# STM32N645 register map
File version: 1.0
CPU: CM55 r0p1, little endian, no MPU, FPU, vendor SysTick, 8 interrupt priority bits
Registers are 32-bit, read-write, reset 0x0 unless marked. A register's access mark holds for its fields unless they carry their own. Offsets are from the block's base; [hi:lo] are bit positions; {n}, {i} and the like mark numbered series; 'fields as' and 'values as' point back to an identical list.

## OTG1 — USB on-the-go high-speed
Base 0x48040000
Same registers: OTG2 0x48080000, OTG1_S 0x58040000, OTG2_S 0x58080000
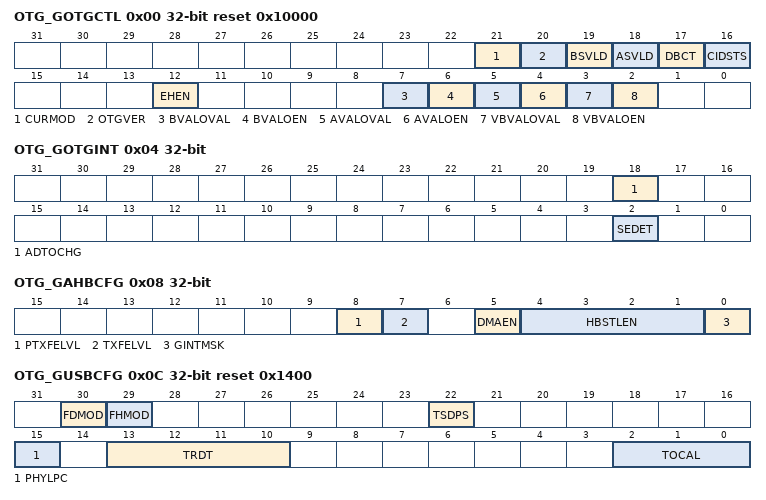
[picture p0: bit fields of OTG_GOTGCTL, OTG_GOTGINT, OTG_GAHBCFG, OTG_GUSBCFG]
0x00 OTG_GOTGCTL access per field reset 0x10000 — OTG control and status register
  [21] CURMOD ro — Current mode of operation
    0=Device mode; 1=Host mode
  [20] OTGVER rw — OTG version
    0=OTG Version 1.3. OTG1.3 is obsolete for new product development.; 1=OTG Version 2.0. In this version the core supports only data line pulsing for SRP.
  [19] BSVLD ro — B-session valid
    0=B-session is not valid; 1=B-session is valid
  [18] ASVLD ro — A-session valid
    0=A-session is not valid; 1=A-session is valid
  [17] DBCT ro — Long/short debounce time
    0=Long debounce time, used for physical connections (100 ms + 2.5 s); 1=Short debounce time, used for soft connections (2.5 s)
  [16] CIDSTS ro — Connector ID status
    0=The OTG controller is in A-device mode; 1=The OTG controller is in B-device mode
  [12] EHEN rw — Embedded host enable
    0=OTG A device state machine is selected; 1=Embedded host state machine is selected
  [7] BVALOVAL rw — B-peripheral session valid override value.
    0=Bvalid value is '0' when BVALOEN = 1; 1=Bvalid value is '1' when BVALOEN = 1
  [6] BVALOEN rw — B-peripheral session valid override enable.
    0=Override is disabled and Bvalid signal from the respective PHY selected is used internally by the core
  [5] AVALOVAL rw — A-peripheral session valid override value.
    0=Avalid value is '0' when AVALOEN = 1; 1=Avalid value is '1' when AVALOEN = 1
  [4] AVALOEN rw — A-peripheral session valid override enable.
    0=Override is disabled and Avalid signal from the respective PHY selected is used internally by the core; 1=Internally Avalid received from the PHY is overridden with AVALOVAL bit value
  [3] VBVALOVAL rw — V less than sub>BUS less than /sub> valid override value.
    0=vbusvalid value is '0' when VBVALOEN = 1; 1=vbusvalid value is '1' when VBVALOEN = 1
  [2] VBVALOEN rw — V less than sub>BUS less than /sub> valid override enable.
    0=Override is disabled and vbusvalid signal from the respective PHY selected is used internally by the core; 1=Internally vbusvalid received from the PHY is overridden with VBVALOVAL bit value
0x04 OTG_GOTGINT — OTG interrupt register
  [18] ADTOCHG — A-device timeout change
  [2] SEDET — Session end detected
0x08 OTG_GAHBCFG — OTG AHB configuration register
  [8] PTXFELVL — Periodic Tx FIFO empty level
    0=PTXFE (in OTG_GINTSTS) interrupt indicates that the Periodic Tx FIFO is half empty; 1=PTXFE (in OTG_GINTSTS) interrupt indicates that the Periodic Tx FIFO is completely empty
  [7] TXFELVL — Tx FIFO empty level
    0=B_0x0_DEVICE_MODE (The TXFE (in OTG_DIEPINTx) interrupt indicates that the IN endpoint Tx FIFO is half empty); 1=B_0x1_DEVICE_MODE (The TXFE (in OTG_DIEPINTx) interrupt indicates that the IN endpoint Tx FIFO is completely empty)
  [5] DMAEN — DMA enabled
    0=The core operates in slave mode; 1=The core operates in DMA mode
  [4:1] HBSTLEN — Burst length/type
  [0] GINTMSK — Global interrupt mask
    0=Mask the interrupt assertion to the application; 1=Unmask the interrupt assertion to the application
0x0C OTG_GUSBCFG reset 0x1400 — OTG USB configuration register
  [30] FDMOD — Force device mode
    0=Normal mode; 1=Force device mode
  [29] FHMOD — Force host mode
    0=Normal mode; 1=Force host mode
  [22] TSDPS — TermSel DLine pulsing selection
    0=Data line pulsing using utmi_txvalid (default); 1=Data line pulsing using utmi_termsel
  [15] PHYLPC — PHY Low-power clock select
    0=480 MHz internal PLL clock; 1=48 MHz external clock
  [13:10] TRDT — USB turnaround time
  [2:0] TOCAL — FS timeout calibration
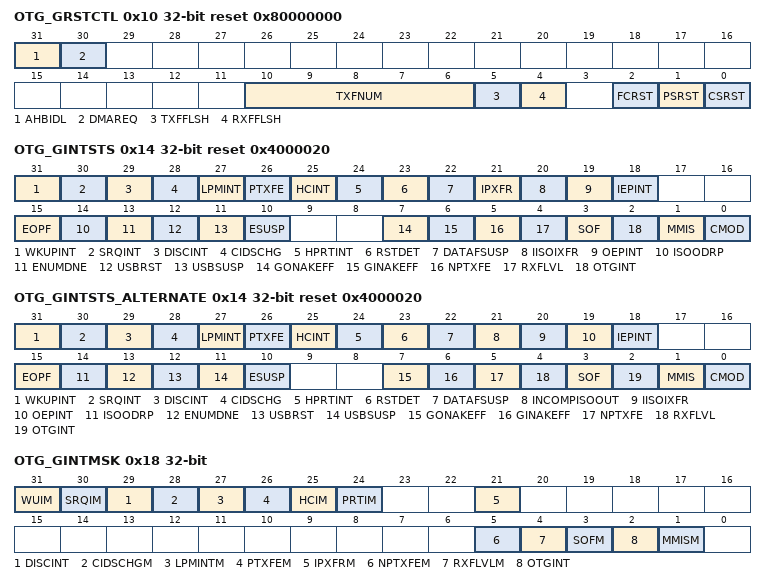
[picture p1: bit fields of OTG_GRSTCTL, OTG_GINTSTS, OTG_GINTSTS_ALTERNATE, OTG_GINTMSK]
0x10 OTG_GRSTCTL access per field reset 0x80000000 — OTG reset register
  [31] AHBIDL ro — AHB master idle
  [30] DMAREQ ro — DMA request signal enabled
  [10:6] TXFNUM rw — Tx FIFO number
    0=B_0x0_HOST_MODE (Non-periodic Tx FIFO flush); 1=B_0x1_HOST_MODE (Periodic Tx FIFO flush); 16=B_0x10_HOST_MODE (Flush all the transmit FIFOs); 2=B_0x2_DEVICE_MODE (Tx FIFO 2 flush); 15=B_0xF_DEVICE_MODE (Tx FIFO 15 flush)
  [5] TXFFLSH rw — Tx FIFO flush
  [4] RXFFLSH rw — Rx FIFO flush
  [2] FCRST rw — Host frame counter reset
  [1] PSRST rw — Partial soft reset
  [0] CSRST rw — Core soft reset
0x14 OTG_GINTSTS access per field reset 0x4000020 — OTG core interrupt register [alternate]
  [31] WKUPINT rw — Resume/remote wake-up detected interrupt
  [30] SRQINT rw — Session request/new session detected interrupt
  [29] DISCINT rw — Disconnect detected interrupt
  [28] CIDSCHG rw — Connector ID status change
  [27] LPMINT rw — LPM interrupt
  [26] PTXFE ro — Periodic Tx FIFO empty
  [25] HCINT ro — Host channels interrupt
  [24] HPRTINT ro — Host port interrupt
  [23] RSTDET rw — Reset detected interrupt
  [22] DATAFSUSP rw — Data fetch suspended
  [21] IPXFR rw — Incomplete periodic transfer
  [20] IISOIXFR rw — Incomplete isochronous IN transfer
  [19] OEPINT ro — OUT endpoint interrupt
  [18] IEPINT ro — IN endpoint interrupt
  [15] EOPF rw — End of periodic frame interrupt
  [14] ISOODRP rw — Isochronous OUT packet dropped interrupt
  [13] ENUMDNE rw — Enumeration done
  [12] USBRST rw — USB reset
  [11] USBSUSP rw — USB suspend
  [10] ESUSP rw — Early suspend
  [7] GONAKEFF ro — Global OUT NAK effective
  [6] GINAKEFF ro — Global IN non-periodic NAK effective
  [5] NPTXFE ro — Non-periodic Tx FIFO empty
  [4] RXFLVL ro — Rx FIFO non-empty
  [3] SOF rw — Start of frame
  [2] OTGINT ro — OTG interrupt
  [1] MMIS rw — Mode mismatch interrupt
  [0] CMOD ro — Current mode of operation
    0=Device mode; 1=Host mode
0x14 OTG_GINTSTS_ALTERNATE access per field reset 0x4000020 (alternate view of OTG_GINTSTS) — OTG core interrupt register [alternate]
  [31] WKUPINT rw — Resume/remote wake-up detected interrupt
  [30] SRQINT rw — Session request/new session detected interrupt
  [29] DISCINT rw — Disconnect detected interrupt
  [28] CIDSCHG rw — Connector ID status change
  [27] LPMINT rw — LPM interrupt
  [26] PTXFE ro — Periodic Tx FIFO empty
  [25] HCINT ro — Host channels interrupt
  [24] HPRTINT ro — Host port interrupt
  [23] RSTDET rw — Reset detected interrupt
  [22] DATAFSUSP rw — Data fetch suspended
  [21] INCOMPISOOUT rw — Incomplete isochronous OUT transfer
  [20] IISOIXFR rw — Incomplete isochronous IN transfer
  [19] OEPINT ro — OUT endpoint interrupt
  [18] IEPINT ro — IN endpoint interrupt
  [15] EOPF rw — End of periodic frame interrupt
  [14] ISOODRP rw — Isochronous OUT packet dropped interrupt
  [13] ENUMDNE rw — Enumeration done
  [12] USBRST rw — USB reset
  [11] USBSUSP rw — USB suspend
  [10] ESUSP rw — Early suspend
  [7] GONAKEFF ro — Global OUT NAK effective
  [6] GINAKEFF ro — Global IN non-periodic NAK effective
  [5] NPTXFE ro — Non-periodic Tx FIFO empty
  [4] RXFLVL ro — Rx FIFO non-empty
  [3] SOF rw — Start of frame
  [2] OTGINT ro — OTG interrupt
  [1] MMIS rw — Mode mismatch interrupt
  [0] CMOD ro — Current mode of operation
    0=Device mode; 1=Host mode
0x18 OTG_GINTMSK access per field — OTG interrupt mask register [alternate]
  [all] fields
    0=Masked interrupt; 1=Unmasked interrupt
  [31] WUIM rw — Resume/remote wake-up detected interrupt mask
  [30] SRQIM rw — Session request/new session detected interrupt mask
  [29] DISCINT rw — Disconnect detected interrupt mask
  [28] CIDSCHGM rw — Connector ID status change mask
  [27] LPMINTM rw — LPM interrupt mask
  [26] PTXFEM rw — Periodic Tx FIFO empty mask
  [25] HCIM rw — Host channels interrupt mask
  [24] PRTIM ro — Host port interrupt mask
  [21] IPXFRM rw — Incomplete periodic transfer mask
  [5] NPTXFEM rw — Non-periodic Tx FIFO empty mask
  [4] RXFLVLM rw — Receive FIFO non-empty mask
  [3] SOFM rw — Start of frame mask
  [2] OTGINT rw — OTG interrupt mask
  [1] MMISM rw — Mode mismatch interrupt mask
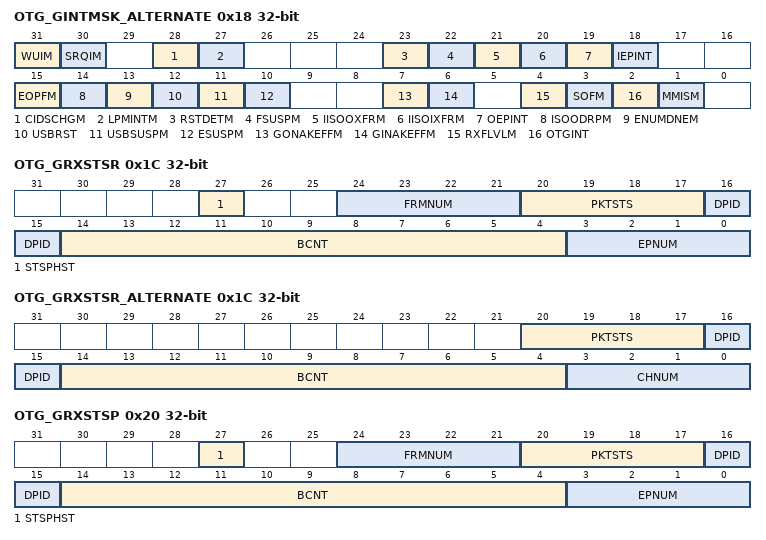
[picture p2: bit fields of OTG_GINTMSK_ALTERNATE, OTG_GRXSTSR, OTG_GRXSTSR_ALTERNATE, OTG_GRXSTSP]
0x18 OTG_GINTMSK_ALTERNATE (alternate view of OTG_GINTMSK) — OTG interrupt mask register [alternate]
  [all] fields
    0=Masked interrupt; 1=Unmasked interrupt
  [31] WUIM — Resume/remote wake-up detected interrupt mask
  [30] SRQIM — Session request/new session detected interrupt mask
  [28] CIDSCHGM — Connector ID status change mask
  [27] LPMINTM — LPM interrupt mask
  [23] RSTDETM — Reset detected interrupt mask
  [22] FSUSPM — Data fetch suspended mask
  [21] IISOOXFRM — Incomplete isochronous OUT transfer mask
  [20] IISOIXFRM — Incomplete isochronous IN transfer mask
  [19] OEPINT — OUT endpoints interrupt mask
  [18] IEPINT — IN endpoints interrupt mask
  [15] EOPFM — End of periodic frame interrupt mask
  [14] ISOODRPM — Isochronous OUT packet dropped interrupt mask
  [13] ENUMDNEM — Enumeration done mask
  [12] USBRST — USB reset mask
  [11] USBSUSPM — USB suspend mask
  [10] ESUSPM — Early suspend mask
  [7] GONAKEFFM — Global OUT NAK effective mask
  [6] GINAKEFFM — Global non-periodic IN NAK effective mask
  [4] RXFLVLM — Receive FIFO non-empty mask
  [3] SOFM — Start of frame mask
  [2] OTGINT — OTG interrupt mask
  [1] MMISM — Mode mismatch interrupt mask
0x1C OTG_GRXSTSR ro — OTG receive status debug read register [alternate]
  [27] STSPHST — Status phase start
  [24:21] FRMNUM — Frame number
  [20:17] PKTSTS — Packet status
    1=Global OUT NAK (triggers an interrupt); 2=OUT data packet received; 3=OUT transfer completed (triggers an interrupt); 4=SETUP transaction completed (triggers an interrupt); 6=SETUP data packet received
  [16:15] DPID — Data PID
    0=DATA0; 2=DATA1; 1=DATA2; 3=MDATA
  [14:4] BCNT — Byte count
  [3:0] EPNUM — Endpoint number
0x1C OTG_GRXSTSR_ALTERNATE ro (alternate view of OTG_GRXSTSR) — OTG receive status debug read register [alternate]
  [20:17] PKTSTS — Packet status
    2=IN data packet received; 3=IN transfer completed (triggers an interrupt); 5=Data toggle error (triggers an interrupt); 7=Channel halted (triggers an interrupt)
  [16:15] DPID — Data PID
    0=DATA0; 2=DATA1; 1=DATA2; 3=MDATA
  [14:4] BCNT — Byte count
  [3:0] CHNUM — Channel number
0x20 OTG_GRXSTSP ro — OTG status read and pop registers
  fields as OTG_GRXSTSR
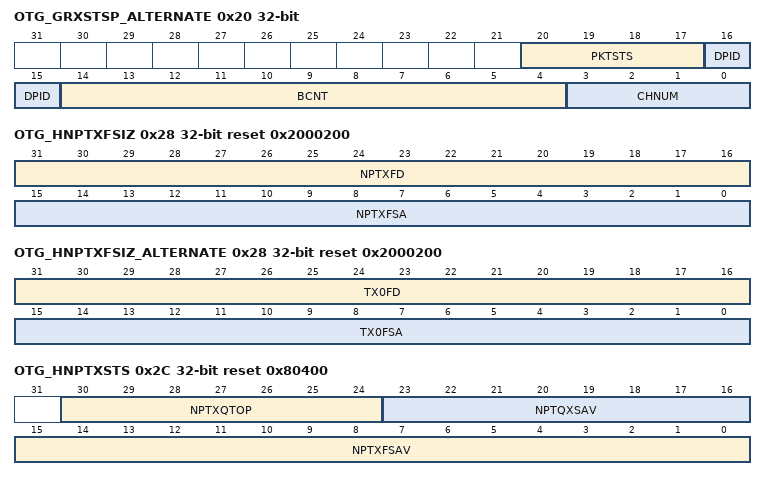
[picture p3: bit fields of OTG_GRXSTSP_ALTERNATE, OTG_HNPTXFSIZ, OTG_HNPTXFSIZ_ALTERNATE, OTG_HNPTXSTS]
0x20 OTG_GRXSTSP_ALTERNATE ro (alternate view of OTG_GRXSTSP) — OTG status read and pop registers
  fields as OTG_GRXSTSR_ALTERNATE
0x24 OTG_GRXFSIZ reset 0x400 — OTG receive FIFO size register
  [15:0] RXFD — Rx FIFO depth
0x28 OTG_HNPTXFSIZ reset 0x2000200 — OTG host non-periodic transmit FIFO size register [alternate]
  [31:16] NPTXFD — Non-periodic Tx FIFO depth
  [15:0] NPTXFSA — Non-periodic transmit RAM start address
0x28 OTG_HNPTXFSIZ_ALTERNATE reset 0x2000200 (alternate view of OTG_HNPTXFSIZ) — OTG host non-periodic transmit FIFO size register [alternate]
  [31:16] TX0FD — Endpoint 0 Tx FIFO depth
  [15:0] TX0FSA — Endpoint 0 transmit RAM start address
0x2C OTG_HNPTXSTS ro reset 0x80400 — OTG non-periodic transmit FIFO/queue status register
  [30:24] NPTXQTOP — Top of the non-periodic transmit request queue
  [23:16] NPTQXSAV — Non-periodic transmit request queue space available
    0=Non-periodic transmit request queue is full; 1=1 location available
  [15:0] NPTXFSAV — Non-periodic Tx FIFO space available
    0=Non-periodic Tx FIFO is full; 1=1 word available
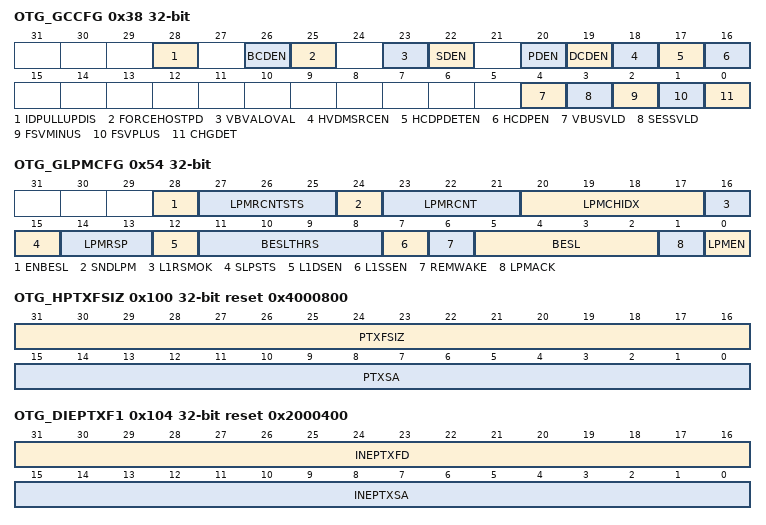
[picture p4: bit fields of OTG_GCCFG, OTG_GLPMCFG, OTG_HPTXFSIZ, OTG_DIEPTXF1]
0x38 OTG_GCCFG access per field (reset mask 0xFFFF0000) — OTG general core configuration register
  [28] IDPULLUPDIS rw — Disable ID pin pull-up
    0=Enables ID pin pull-up; 1=Disable ID pin pull-up
  [26] BCDEN rw — Force Battery charging (BC) mode
    0=Normal USB mode; 1=Battery Charging mode
  [25] FORCEHOSTPD rw — Force host mode pull-downs
    0=Do not force host mode pull-downs; 1=Force host mode pull-downs
  [23] VBVALOVAL rw — Software override value of the VBUS B-session detection
    0=B-session inactive; 1=B-session active
  [22] SDEN rw — Secondary detection enable
    0=Secondary detection disabled; 1=Secondary detection enabled
  [20] PDEN rw — Primary detection enable
    0=Primary detection disabled; 1=Primary detection enabled
  [19] DCDEN rw — Data Contact Detection enable
    0=Data Contact Detection disabled; 1=Data Contact Detection enabled
  [18] HVDMSRCEN rw — Host CDP port Voltage source enable on DM
    0=DM voltage source disabled; 1=DM Voltage source enabled
  [17] HCDPDETEN rw — Host CDP port voltage detector enable on DP
    0=DP voltage detection disabled; 1=DP voltage detection enabled
  [16] HCDPEN rw — Host CDP behavior enable
    0=Disable CDP behavior; 1=Enable CDP behavior
  [4] VBUSVLD ro — VBUS valid indicator
    0=VBUS is below VBUS valid threshold; 1=VBUS is above VBUS valid threshold
  [3] SESSVLD ro — VBUS session indicator
    0=VBUS is below VBUS session threshold; 1=VBUS is above VBUS session threshold
  [2] FSVMINUS ro — Single-Ended DM indicator
    0=DM voltage at low level; 1=DM voltage at high level
  [1] FSVPLUS ro — Single-Ended DP indicator
    0=DM voltage at low level; 1=DM voltage at high level
  [0] CHGDET ro — Charger detection, result of the current mode (primary or secondary).
    0=Low value on pin; 1=High value on pin
0x3C OTG_CID reset 0x5000 — OTG core ID register
  [31:0] PRODUCT_ID
0x54 OTG_GLPMCFG access per field — OTG core LPM configuration register
  [28] ENBESL rw — Enable best effort service latency
    0=The core works as described in the following document:; 1=The core works as described in the LPM Errata:
  [27:25] LPMRCNTSTS ro — LPM retry count status
  [24] SNDLPM rw — Send LPM transaction
  [23:21] LPMRCNT rw — LPM retry count
  [20:17] LPMCHIDX rw — LPM Channel Index
  [16] L1RSMOK ro — Sleep state resume OK
    1=The application or host can start resume from Sleep state; 0=The application or host cannot start resume from Sleep state
  [15] SLPSTS ro — Port sleep status
    0=Core not in L1; 1=Core in L1
  [14:13] LPMRSP ro — LPM response
    3=ACK; 2=NYET; 1=STALL; 0=ERROR (No handshake response)
  [12] L1DSEN rw — L1 deep sleep enable
  [11:8] BESLTHRS rw — BESL threshold
    0=75; 1=100; 2=150; 3=250; 4=350; 5=450; 6=950
  [7] L1SSEN rw — L1 Shallow Sleep enable
  [6] REMWAKE rw — bRemoteWake value
  [5:2] BESL rw — Best effort service latency
    0=125; 1=150; 2=200; 3=300; 4=400; 5=500; 6=1000; 7=2000; 8=3000; 9=4000; 10=5000; 11=6000; 12=7000; 13=8000; 14=9000; 15=10000
  [1] LPMACK rw — LPM token acknowledge enable
    1=ACK; 0=NYET
  [0] LPMEN rw — LPM support enable
    0=LPM capability is not enabled; 1=LPM capability is enabled
0x100 OTG_HPTXFSIZ reset 0x4000800 — OTG host periodic transmit FIFO size register
  [31:16] PTXFSIZ — Host periodic Tx FIFO depth
  [15:0] PTXSA — Host periodic Tx FIFO start address
0x104 OTG_DIEPTXF1 reset 0x2000400 — OTG device IN endpoint transmit FIFO 1 size register
  [31:16] INEPTXFD — IN endpoint Tx FIFO depth
  [15:0] INEPTXSA — IN endpoint FIFOx transmit RAM start address
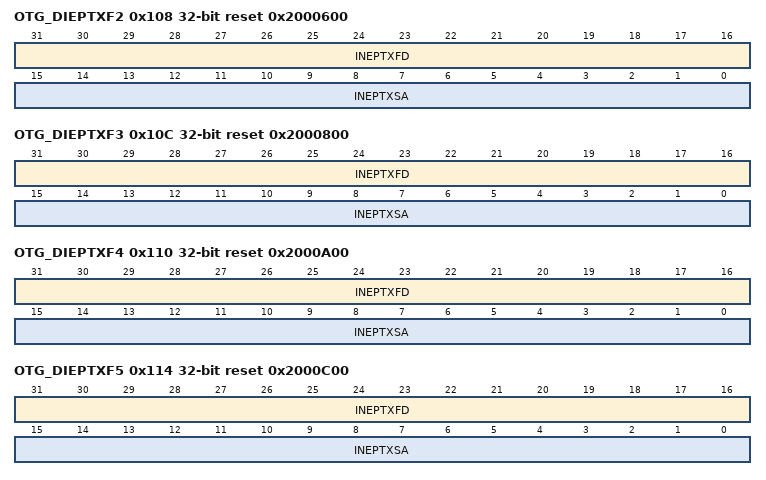
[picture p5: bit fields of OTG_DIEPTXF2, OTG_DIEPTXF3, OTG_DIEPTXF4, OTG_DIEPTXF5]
0x108 OTG_DIEPTXF2 reset 0x2000600 — OTG device IN endpoint transmit FIFO 2 size register
  fields as OTG_DIEPTXF1
0x10C OTG_DIEPTXF3 reset 0x2000800 — OTG device IN endpoint transmit FIFO 3 size register
  fields as OTG_DIEPTXF1
0x110 OTG_DIEPTXF4 reset 0x2000A00 — OTG device IN endpoint transmit FIFO 4 size register
  fields as OTG_DIEPTXF1
0x114 OTG_DIEPTXF5 reset 0x2000C00 — OTG device IN endpoint transmit FIFO 5 size register
  fields as OTG_DIEPTXF1
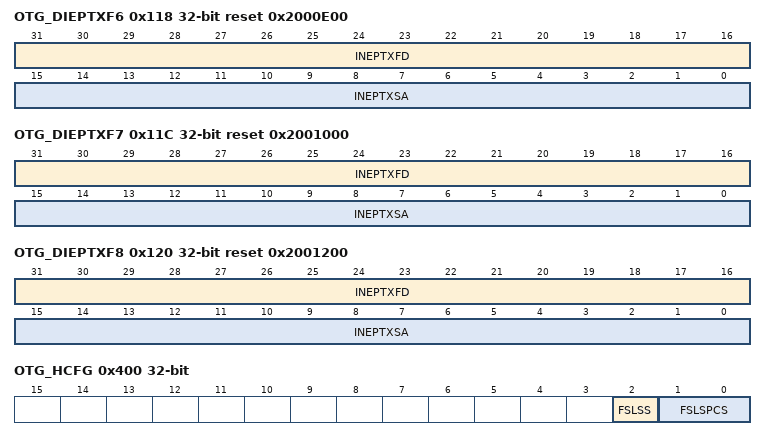
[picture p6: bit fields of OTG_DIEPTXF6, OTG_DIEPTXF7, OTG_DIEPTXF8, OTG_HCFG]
0x118 OTG_DIEPTXF6 reset 0x2000E00 — OTG device IN endpoint transmit FIFO 6 size register
  fields as OTG_DIEPTXF1
0x11C OTG_DIEPTXF7 reset 0x2001000 — OTG device IN endpoint transmit FIFO 7 size register
  fields as OTG_DIEPTXF1
0x120 OTG_DIEPTXF8 reset 0x2001200 — OTG device IN endpoint transmit FIFO 8 size register
  fields as OTG_DIEPTXF1
0x400 OTG_HCFG access per field — OTG host configuration register
  [2] FSLSS ro — FS- and LS-only support
  [1:0] FSLSPCS rw — FS/LS PHY clock select
    1=B_0x1_FS_HOST_MODE (PHY clock is running at 48 MHz); 2=B_0x2_LS_HOST_MODE (Select 6 MHz PHY clock frequency)
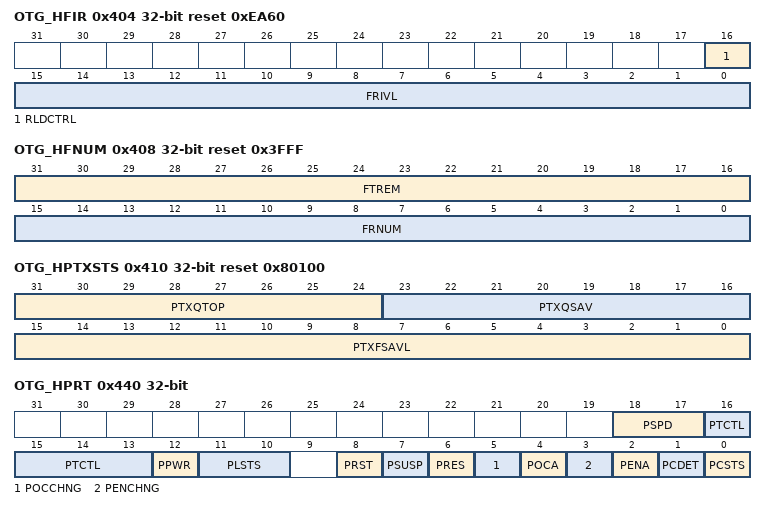
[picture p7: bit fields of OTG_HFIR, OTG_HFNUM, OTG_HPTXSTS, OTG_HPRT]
0x404 OTG_HFIR reset 0xEA60 — OTG host frame interval register
  [16] RLDCTRL — Reload control
    0=The HFIR cannot be reloaded dynamically; 1=The HFIR can be dynamically reloaded during run time
  [15:0] FRIVL — Frame interval
0x408 OTG_HFNUM ro reset 0x3FFF — OTG host frame number/frame time remaining register
  [31:16] FTREM — Frame time remaining
  [15:0] FRNUM — Frame number
0x410 OTG_HPTXSTS ro reset 0x80100 — OTG_Host periodic transmit FIFO/queue status register
  [31:24] PTXQTOP — Top of the periodic transmit request queue
  [23:16] PTXQSAV — Periodic transmit request queue space available
    0=Periodic transmit request queue is full; 1=1 location available
  [15:0] PTXFSAVL — Periodic transmit data FIFO space available
    0=Periodic Tx FIFO is full; 1=1 word available
0x414 OTG_HAINT ro — OTG host all channels interrupt register
  [15:0] HAINT — Channel interrupts
0x418 OTG_HAINTMSK — OTG host all channels interrupt mask register
  [15:0] HAINTM — Channel interrupt mask
    0=Masked interrupt; 1=Unmasked interrupt
0x440 OTG_HPRT access per field — OTG host port control and status register
  [18:17] PSPD ro — Port speed
    1=Full speed; 2=Low speed; 0=High speed
  [16:13] PTCTL rw — Port test control
    0=Test mode disabled; 1=Test_J mode; 2=Test_K mode; 3=Test_SE0_NAK mode; 4=Test_Packet mode; 5=Test_Force_Enable
  [12] PPWR rw — Port power
    0=Power off; 1=Power on
  [11:10] PLSTS ro — Port line status
  [8] PRST rw — Port reset
    0=Port not in reset; 1=Port in reset
  [7] PSUSP rw — Port suspend
    0=Port not in suspend mode; 1=Port in suspend mode
  [6] PRES rw — Port resume
    0=No resume driven; 1=Resume driven
  [5] POCCHNG rw — Port overcurrent change
  [4] POCA ro — Port overcurrent active
    0=No overcurrent condition; 1=Overcurrent condition
  [3] PENCHNG rw — Port enable/disable change
  [2] PENA rw — Port enable
    0=Port disabled; 1=Port enabled
  [1] PCDET rw — Port connect detected
  [0] PCSTS ro — Port connect status
    0=No device is attached to the port; 1=A device is attached to the port
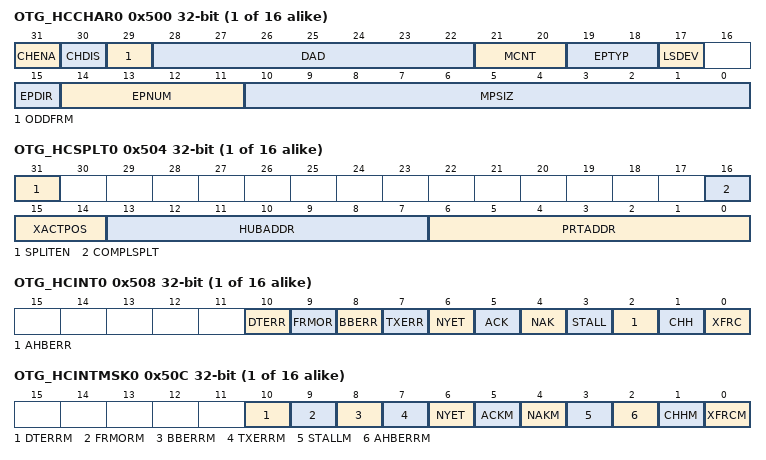
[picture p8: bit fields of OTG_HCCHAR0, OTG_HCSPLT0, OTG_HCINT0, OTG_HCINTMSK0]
{0x500+0x20*i} OTG_HCCHAR{i} (i=0..15) — OTG host channel {i} characteristics register
  [31] CHENA — Channel enable
    0=Channel disabled; 1=Channel enabled
  [30] CHDIS — Channel disable
  [29] ODDFRM — Odd frame
    0=Even frame; 1=Odd frame
  [28:22] DAD — Device address
  [21:20] MCNT — Multicount
    1=1 transaction; 2=2 transactions per frame to be issued for this endpoint; 3=3 transactions per frame to be issued for this endpoint
  [19:18] EPTYP — Endpoint type
    0=Control; 1=Isochronous; 2=Bulk; 3=Interrupt
  [17] LSDEV — Low-speed device
  [15] EPDIR — Endpoint direction
    0=OUT; 1=IN
  [14:11] EPNUM — Endpoint number
  [10:0] MPSIZ — Maximum packet size
{0x504+0x20*i} OTG_HCSPLT{i} (i=0..15) — OTG host channel {i} split control register
  [31] SPLITEN — Split enable
  [16] COMPLSPLT — Do complete split
  [15:14] XACTPOS — Transaction position
    3=All. This is the entire data payload of this transaction (which is less than or equal to 188 bytes); 2=Begin. This is the first data payload of this transaction (which is larger than 188 bytes); 0=Mid. This is the middle payload of this transaction (which is larger than 188 bytes); 1=End. This is the last payload of this transaction (which is larger than 188 bytes)
  [13:7] HUBADDR — Hub address
  [6:0] PRTADDR — Port address
{0x508+0x20*i} OTG_HCINT{i} (i=0..15) — OTG host channel {i} interrupt register
  [10] DTERR — Data toggle error.
  [9] FRMOR — Frame overrun.
  [8] BBERR — Babble error.
  [7] TXERR — Transaction error.
  [6] NYET — Not yet ready response received interrupt.
  [5] ACK — ACK response received/transmitted interrupt.
  [4] NAK — NAK response received interrupt.
  [3] STALL — STALL response received interrupt.
  [2] AHBERR — AHB error
  [1] CHH — Channel halted.
  [0] XFRC — Transfer completed.
{0x50C+0x20*i} OTG_HCINTMSK{i} (i=0..15) — OTG host channel {i} interrupt mask register
  [all] fields
    0=Masked interrupt; 1=Unmasked interrupt
  [10] DTERRM — Data toggle error mask.
  [9] FRMORM — Frame overrun mask.
  [8] BBERRM — Babble error mask.
  [7] TXERRM — Transaction error mask.
  [6] NYET — response received interrupt mask.
  [5] ACKM — ACK response received/transmitted interrupt mask.
  [4] NAKM — NAK response received interrupt mask.
  [3] STALLM — STALL response received interrupt mask.
  [2] AHBERRM — AHB error.
  [1] CHHM — Channel halted mask
  [0] XFRCM — Transfer completed mask
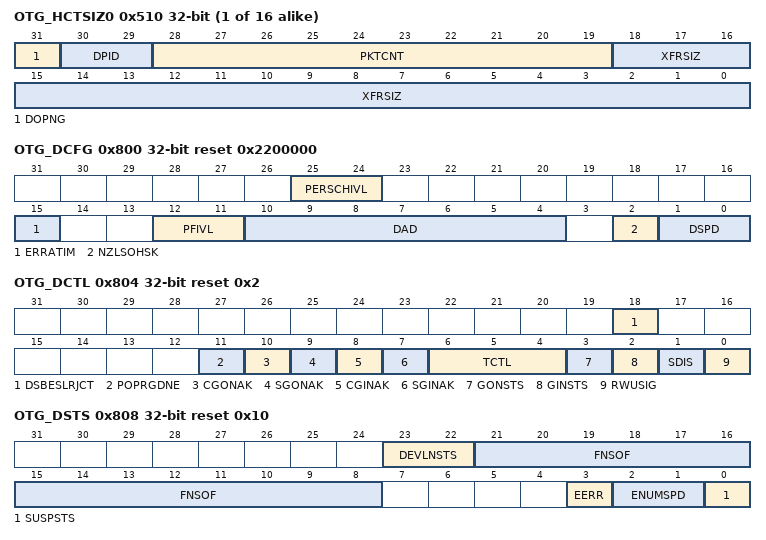
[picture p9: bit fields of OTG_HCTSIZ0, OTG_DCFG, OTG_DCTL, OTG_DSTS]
{0x510+0x20*i} OTG_HCTSIZ{i} (i=0..15) — OTG host channel {i} transfer size register
  [31] DOPNG — Do Ping
  [30:29] DPID — Data PID
    0=DATA0; 1=DATA2; 2=DATA1; 3=SETUP (control) / MDATA (non-control)
  [28:19] PKTCNT — Packet count
  [18:0] XFRSIZ — Transfer size
{0x514+0x20*i} OTG_HCDMA{i} (i=0..15) — OTG host channel {i} DMA address register
  [31:0] DMAADDR — DMA address
0x800 OTG_DCFG reset 0x2200000 — OTG device configuration register
  [25:24] PERSCHIVL — Periodic schedule interval
    0=25% of (micro)frame; 1=50% of (micro)frame; 2=75% of (micro)frame
  [15] ERRATIM — Erratic error interrupt mask
    1=Mask early suspend interrupt on erratic error; 0=Early suspend interrupt is generated on erratic error
  [12:11] PFIVL — Periodic frame interval
    0=80% of the frame interval; 1=85% of the frame interval; 2=90% of the frame interval; 3=95% of the frame interval
  [10:4] DAD — Device address
  [2] NZLSOHSK — Non-zero-length status OUT handshake
    1=Send a STALL handshake on a nonzero-length status OUT transaction and do not send the received OUT packet to the application; 0=Send the received OUT packet to the application (zero-length or nonzero-length) and send a handshake based on the NAK and STALL bits for the endpoint in the device endpoint control register
  [1:0] DSPD — Device speed
    0=High speed; 1=Full speed
0x804 OTG_DCTL access per field reset 0x2 — OTG device control register
  [18] DSBESLRJCT rw — Deep sleep BESL reject
  [11] POPRGDNE rw — Power-on programming done
  [10] CGONAK wo — Clear global OUT NAK
  [9] SGONAK wo — Set global OUT NAK
  [8] CGINAK wo — Clear global IN NAK
  [7] SGINAK wo — Set global IN NAK
  [6:4] TCTL rw — Test control
    values as OTG_HPRT.PTCTL
  [3] GONSTS ro — Global OUT NAK status
    0=A handshake is sent based on the FIFO status and the NAK and STALL bit settings; 1=No data is written to the Rx FIFO, irrespective of space availability. Sends a NAK handshake on all packets, except on SETUP transactions. All isochronous OUT packets are dropped.
  [2] GINSTS ro — Global IN NAK status
    0=A handshake is sent out based on the data availability in the transmit FIFO; 1=A NAK handshake is sent out on all non-periodic IN endpoints, irrespective of the data availability in the transmit FIFO
  [1] SDIS rw — Soft disconnect
    0=Normal operation. When this bit is cleared after a soft disconnect, the core generates a device connect event to the USB host. When the device is reconnected, the USB host restarts device enumeration.; 1=The core generates a device disconnect event to the USB host
  [0] RWUSIG rw — Remote wake-up signaling
0x808 OTG_DSTS ro reset 0x10 — OTG device status register
  [23:22] DEVLNSTS — Device line status
  [21:8] FNSOF — Frame number of the received SOF
  [3] EERR — Erratic error
  [2:1] ENUMSPD — Enumerated speed
    0=High Speed; 1=Full Speed
  [0] SUSPSTS — Suspend status
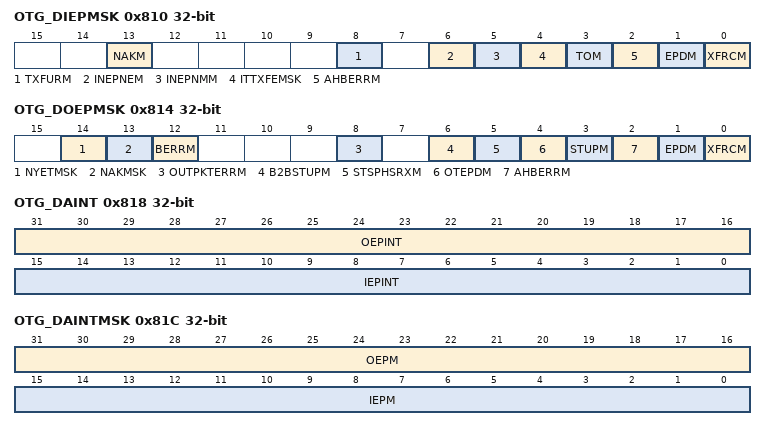
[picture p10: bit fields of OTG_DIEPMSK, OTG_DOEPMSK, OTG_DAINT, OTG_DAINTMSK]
0x810 OTG_DIEPMSK — OTG device IN endpoint common interrupt mask register
  [all] fields
    0=Masked interrupt; 1=Unmasked interrupt
  [13] NAKM — NAK interrupt mask
  [8] TXFURM — FIFO underrun mask
  [6] INEPNEM — IN endpoint NAK effective mask
  [5] INEPNMM — IN token received with EP mismatch mask
  [4] ITTXFEMSK — IN token received when Tx FIFO empty mask
  [3] TOM — Timeout condition mask (Non-isochronous endpoints)
  [2] AHBERRM — AHB error mask
  [1] EPDM — Endpoint disabled interrupt mask
  [0] XFRCM — Transfer completed interrupt mask
0x814 OTG_DOEPMSK — OTG device OUT endpoint common interrupt mask register
  [all] fields
    0=Masked interrupt; 1=Unmasked interrupt
  [14] NYETMSK — NYET interrupt mask
  [13] NAKMSK — NAK interrupt mask
  [12] BERRM — Babble error interrupt mask
  [8] OUTPKTERRM — Out packet error mask
  [6] B2BSTUPM — Back-to-back SETUP packets received mask
  [5] STSPHSRXM — Status phase received for control write mask
  [4] OTEPDM — OUT token received when endpoint disabled mask. Applies to control OUT endpoints only.
  [3] STUPM — STUPM: SETUP phase done mask. Applies to control endpoints only.
  [2] AHBERRM — AHB error mask
  [1] EPDM — Endpoint disabled interrupt mask
  [0] XFRCM — Transfer completed interrupt mask
0x818 OTG_DAINT ro — OTG device all endpoints interrupt register
  [31:16] OEPINT — OUT endpoint interrupt bits
  [15:0] IEPINT — IN endpoint interrupt bits
0x81C OTG_DAINTMSK — OTG all endpoints interrupt mask register
  [31:16] OEPM — OUT EP interrupt mask bits
    0=Masked interrupt; 1=Unmasked interrupt
  [15:0] IEPM — IN EP interrupt mask bits
    0=Masked interrupt; 1=Unmasked interrupt
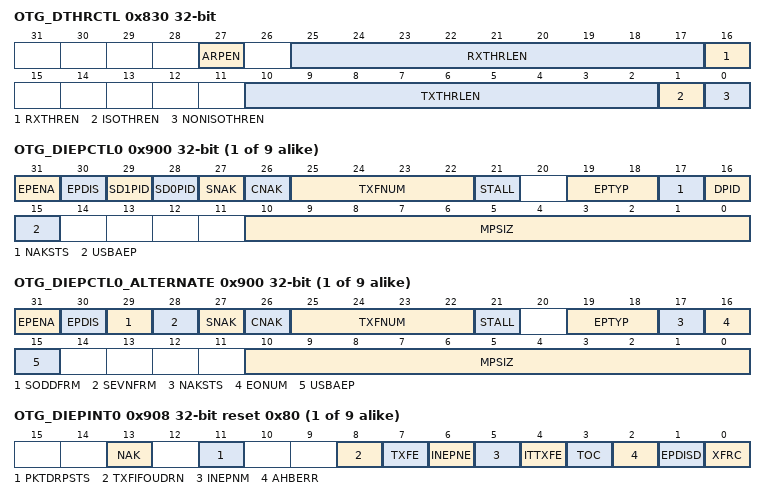
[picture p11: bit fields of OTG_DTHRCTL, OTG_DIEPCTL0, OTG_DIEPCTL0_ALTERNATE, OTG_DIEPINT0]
0x830 OTG_DTHRCTL — OTG device threshold control register
  [27] ARPEN — Arbiter parking enable
  [25:17] RXTHRLEN — Receive threshold length
  [16] RXTHREN — Receive threshold enable
  [10:2] TXTHRLEN — Transmit threshold length
  [1] ISOTHREN — ISO IN endpoint threshold enable
  [0] NONISOTHREN — Nonisochronous IN endpoints threshold enable
0x834 OTG_DIEPEMPMSK — OTG device IN endpoint FIFO empty interrupt mask register
  [15:0] INEPTXFEM — IN EP Tx FIFO empty interrupt mask bits
    0=Masked interrupt; 1=Unmasked interrupt
{0x900+0x20*i} OTG_DIEPCTL{i} access per field (i=0..8) — OTG device IN endpoint {i} control register [alternate]
  [31] EPENA rw — Endpoint enable
  [30] EPDIS rw — Endpoint disable
  [29] SD1PID wo — Set DATA1 PID
  [28] SD0PID wo — Set DATA0 PID
  [27] SNAK wo — Set NAK
  [26] CNAK wo — Clear NAK
  [25:22] TXFNUM rw — Tx FIFO number
  [21] STALL rw — STALL handshake
  [19:18] EPTYP rw — Endpoint type
    0=Control; 1=Isochronous; 2=Bulk; 3=Interrupt
  [17] NAKSTS ro — NAK status
    0=The core is transmitting non-NAK handshakes based on the FIFO status; 1=The core is transmitting NAK handshakes on this endpoint
  [16] DPID ro — Endpoint data PID
    0=DATA0; 1=DATA1
  [15] USBAEP rw — USB active endpoint
  [10:0] MPSIZ rw — Maximum packet size
{0x900+0x20*i} OTG_DIEPCTL{i}_ALTERNATE access per field (alternate view of OTG_DIEPCTL{i}) (i=0..8) — OTG device IN endpoint {i} control register [alternate]
  [31] EPENA rw — Endpoint enable
  [30] EPDIS rw — Endpoint disable
  [29] SODDFRM wo — Set odd frame
  [28] SEVNFRM wo — Set even frame
  [27] SNAK wo — Set NAK
  [26] CNAK wo — Clear NAK
  [25:22] TXFNUM rw — Tx FIFO number
  [21] STALL rw — STALL handshake
  [19:18] EPTYP rw — Endpoint type
    0=Control; 1=Isochronous; 2=Bulk; 3=Interrupt
  [17] NAKSTS ro — NAK status
    values as OTG_DIEPCTL0.NAKSTS
  [16] EONUM ro — Even/odd frame
    0=Even frame; 1=Odd frame
  [15] USBAEP rw — USB active endpoint
  [10:0] MPSIZ rw — Maximum packet size
{0x908+0x20*i} OTG_DIEPINT{i} access per field reset 0x80 (i=0..8) — OTG device IN endpoint {i} interrupt register
  [13] NAK rw — NAK input
  [11] PKTDRPSTS rw — Packet dropped status
  [8] TXFIFOUDRN rw — Transmit Fifo Underrun (TxfifoUndrn)
  [7] TXFE ro — Transmit FIFO empty
  [6] INEPNE rw — IN endpoint NAK effective
  [5] INEPNM rw — IN token received with EP mismatch
  [4] ITTXFE rw — IN token received when Tx FIFO is empty
  [3] TOC rw — Timeout condition
  [2] AHBERR rw — AHB error
  [1] EPDISD rw — Endpoint disabled interrupt
  [0] XFRC rw — Transfer completed interrupt
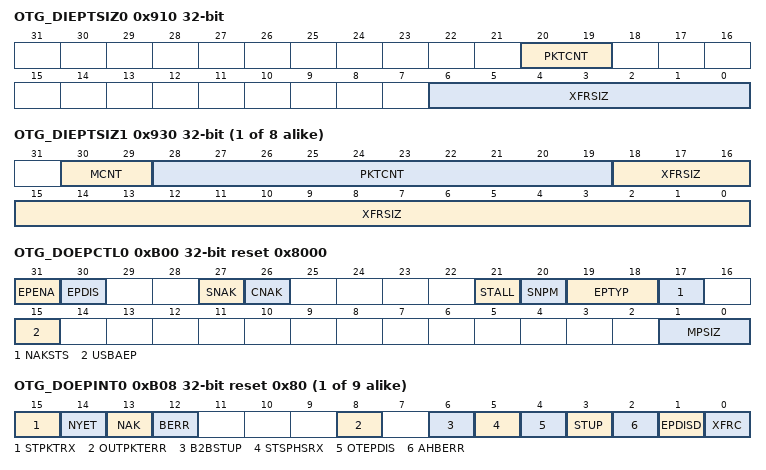
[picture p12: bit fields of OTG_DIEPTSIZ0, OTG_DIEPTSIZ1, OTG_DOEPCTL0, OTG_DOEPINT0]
0x910 OTG_DIEPTSIZ0 — OTG device IN endpoint 0 transfer size register
  [20:19] PKTCNT — Packet count
  [6:0] XFRSIZ — Transfer size
{0x914+0x20*i} OTG_DIEPDMA{i} (i=0..8) — OTG device IN endpoint {i} DMA address register
  [31:0] DMAADDR — DMA Address
{0x918+0x20*i} OTG_DTXFSTS{i} ro reset 0x200 (i=0..8) — OTG device IN endpoint transmit FIFO status register
  [15:0] INEPTFSAV — IN endpoint Tx FIFO space available
    0=Endpoint Tx FIFO is full; 1=1 word available; 2=2 words available
{0x910+0x20*i} OTG_DIEPTSIZ{i} (i=1..8) — OTG device IN endpoint {i} transfer size register
  [30:29] MCNT — Multi count
    1=1 packet; 2=2 packets; 3=3 packets
  [28:19] PKTCNT — Packet count
  [18:0] XFRSIZ — Transfer size
0xB00 OTG_DOEPCTL0 access per field reset 0x8000 — OTG device control OUT endpoint 0 control register
  [31] EPENA wo — Endpoint enable
  [30] EPDIS ro — Endpoint disable
  [27] SNAK wo — Set NAK
  [26] CNAK wo — Clear NAK
  [21] STALL rw — STALL handshake
  [20] SNPM rw — Snoop mode
  [19:18] EPTYP ro — Endpoint type
  [17] NAKSTS ro — NAK status
    values as OTG_DIEPCTL0.NAKSTS
  [15] USBAEP ro — USB active endpoint
  [1:0] MPSIZ ro — Maximum packet size
    0=64 bytes; 1=32 bytes; 2=16 bytes; 3=8 bytes
{0xB08+0x20*i} OTG_DOEPINT{i} reset 0x80 (i=0..8) — OTG device OUT endpoint {i} interrupt register
  [15] STPKTRX — Setup packet received
  [14] NYET — NYET interrupt
  [13] NAK — NAK input
  [12] BERR — Babble error interrupt
  [8] OUTPKTERR — OUT packet error
  [6] B2BSTUP — Back-to-back SETUP packets received
  [5] STSPHSRX — Status phase received for control write
  [4] OTEPDIS — OUT token received when endpoint disabled
  [3] STUP — SETUP phase done
  [2] AHBERR — AHB error
  [1] EPDISD — Endpoint disabled interrupt
  [0] XFRC — Transfer completed interrupt
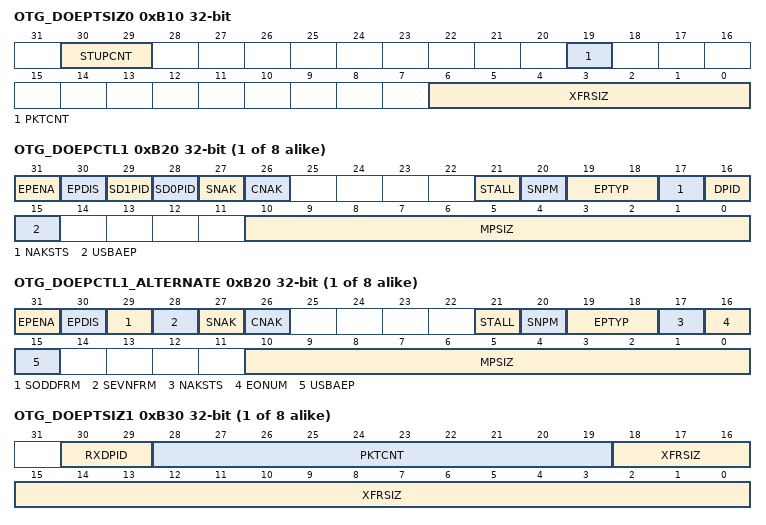
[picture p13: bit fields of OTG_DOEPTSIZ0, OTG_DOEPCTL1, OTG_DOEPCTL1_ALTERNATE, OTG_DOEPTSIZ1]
0xB10 OTG_DOEPTSIZ0 — OTG device OUT endpoint 0 transfer size register
  [30:29] STUPCNT — SETUP packet count
    1=1 packet; 2=2 packets; 3=3 packets
  [19] PKTCNT — Packet count
  [6:0] XFRSIZ — Transfer size
{0xB14+0x20*i} OTG_DOEPDMA{i} (i=0..8) — OTG device OUT endpoint {i} DMA address register
  [31:0] DMAADDR — DMA Address
{0xB00+0x20*i} OTG_DOEPCTL{i} access per field (i=1..8) — OTG device OUT endpoint {i} control register [alternate]
  [31] EPENA rw — Endpoint enable
  [30] EPDIS rw — Endpoint disable
  [29] SD1PID wo — Set DATA1 PID
  [28] SD0PID wo — Set DATA0 PID
  [27] SNAK wo — Set NAK
  [26] CNAK wo — Clear NAK
  [21] STALL rw — STALL handshake
  [20] SNPM rw — Snoop mode
  [19:18] EPTYP rw — Endpoint type
    0=Control; 1=Isochronous; 2=Bulk; 3=Interrupt
  [17] NAKSTS ro — NAK status
    values as OTG_DIEPCTL0.NAKSTS
  [16] DPID ro — Endpoint data PID
    0=DATA0; 1=DATA1
  [15] USBAEP rw — USB active endpoint
  [10:0] MPSIZ rw — Maximum packet size
{0xB00+0x20*i} OTG_DOEPCTL{i}_ALTERNATE access per field (alternate view of OTG_DOEPCTL{i}) (i=1..8) — OTG device OUT endpoint {i} control register [alternate]
  [31] EPENA rw — Endpoint enable
  [30] EPDIS rw — Endpoint disable
  [29] SODDFRM wo — Set odd frame
  [28] SEVNFRM wo — Set even frame
  [27] SNAK wo — Set NAK
  [26] CNAK wo — Clear NAK
  [21] STALL rw — STALL handshake
  [20] SNPM rw — Snoop mode
  [19:18] EPTYP rw — Endpoint type
    0=Control; 1=Isochronous; 2=Bulk; 3=Interrupt
  [17] NAKSTS ro — NAK status
    values as OTG_DIEPCTL0.NAKSTS
  [16] EONUM ro — Even/odd frame
    0=Even frame; 1=Odd frame
  [15] USBAEP rw — USB active endpoint
  [10:0] MPSIZ rw — Maximum packet size
{0xB10+0x20*i} OTG_DOEPTSIZ{i} (i=1..8) — OTG device OUT endpoint {i} transfer size register
  [30:29] RXDPID — Received data PID
    0=B_0x0_ISOCHRONOUS_OUT_ENDPOINTS (DATA0); 1=B_0x1_ISOCHRONOUS_OUT_ENDPOINTS (DATA2); 2=B_0x2_ISOCHRONOUS_OUT_ENDPOINTS (DATA1); 3=B_0x3_ISOCHRONOUS_OUT_ENDPOINTS (MDATA)
  [28:19] PKTCNT — Packet count
  [18:0] XFRSIZ — Transfer size
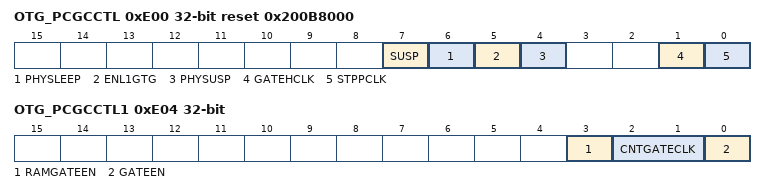
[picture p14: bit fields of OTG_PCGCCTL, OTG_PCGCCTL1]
0xE00 OTG_PCGCCTL access per field reset 0x200B8000 — OTG power and clock gating control register
  [7] SUSP ro — Deep Sleep
  [6] PHYSLEEP ro — PHY in Sleep
  [5] ENL1GTG rw — Enable sleep clock gating
  [4] PHYSUSP ro — PHY suspended
  [1] GATEHCLK rw
  [0] STPPCLK rw — Stop PHY clock
0xE04 OTG_PCGCCTL1 — OTG power and clock gating control register 1
  [3] RAMGATEEN — Enable RAM clock gating
  [2:1] CNTGATECLK — Counter for clock gating
    0=64 clocks; 1=128 clocks
  [0] GATEEN — Enable active clock gating
